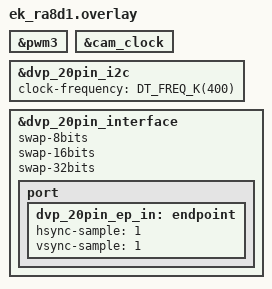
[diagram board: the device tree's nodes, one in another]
/*
 * Copyright (c) 2025 Renesas Electronics Corporation
 *
 * SPDX-License-Identifier: Apache-2.0
 */

&pwm3 {
	status = "okay";
};

&cam_clock {
	status = "okay";
};

&dvp_20pin_i2c {
	clock-frequency = <DT_FREQ_K(400)>;
};

&dvp_20pin_interface {
	swap-8bits;
	swap-16bits;
	swap-32bits;

	port {
		dvp_20pin_ep_in: endpoint {
			hsync-sample = <1>;
			vsync-sample = <1>;
		};
	};
};
